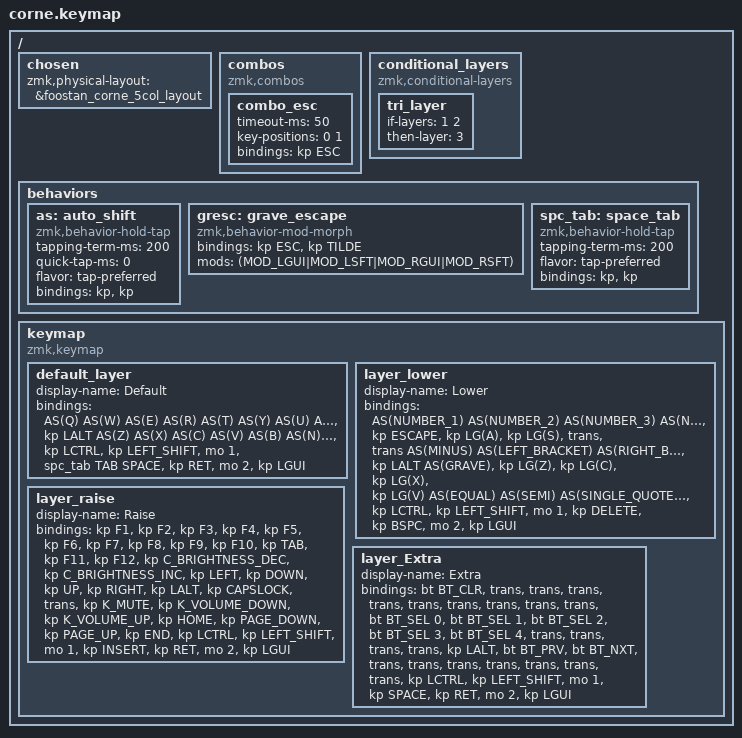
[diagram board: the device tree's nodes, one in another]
/*
 * Copyright (c) 2020 The ZMK Contributors
 *
 * SPDX-License-Identifier: MIT
 */

#include <behaviors.dtsi>
#include <dt-bindings/zmk/keys.h>
#include <dt-bindings/zmk/bt.h>


#define AS(keycode) &as LS(keycode) keycode

/ {
    chosen {
        zmk,physical-layout = &foostan_corne_5col_layout;
    };
 
    combos {
        compatible = "zmk,combos";
        combo_esc {
            timeout-ms = <50>;
            key-positions = <0 1>;
            bindings = <&kp ESC>;
        };
    };

    conditional_layers {
        compatible = "zmk,conditional-layers";
        tri_layer {
            if-layers = <1 2>;
            then-layer = <3>;
        };
    };

    behaviors {
        as: auto_shift {
            compatible = "zmk,behavior-hold-tap";
            #binding-cells = <2>;
            tapping-term-ms = <200>;
            quick-tap-ms = <0>;
            flavor = "tap-preferred";
            bindings = <&kp>, <&kp>;
        };
        
        gresc: grave_escape {
            compatible = "zmk,behavior-mod-morph";
            #binding-cells = <0>;
            bindings = <&kp ESC>, <&kp TILDE>;
            mods = <(MOD_LGUI|MOD_LSFT|MOD_RGUI|MOD_RSFT)>;
        };

        spc_tab: space_tab {
            compatible = "zmk,behavior-hold-tap";
            #binding-cells = <2>;
            tapping-term-ms = <200>;
            flavor = "tap-preferred";
            bindings = <&kp>, <&kp>;
        };
    };
    keymap {
        compatible = "zmk,keymap";

        default_layer {
            display-name = "Default";
            bindings = <
  AS(Q)   AS(W)   AS(E)   AS(R)   AS(T)   AS(Y)   AS(U)   AS(I)   AS(O)   AS(P)   AS(A)   AS(S)   AS(D)   AS(F)   AS(G)   AS(H)   AS(J)   AS(K)   AS(L)  &kp LALT   AS(Z)   AS(X)   AS(C)   AS(V)   AS(B)   AS(N)   AS(M)  AS(COMMA)  AS(DOT)  &kp LCTRL  &kp LEFT_SHIFT   &mo 1  &spc_tab TAB SPACE  &kp RET   &mo 2  &kp LGUI
            >;
        };

        layer_lower {
            display-name = "Lower";
            bindings = <
 AS(NUMBER_1)  AS(NUMBER_2)  AS(NUMBER_3)  AS(NUMBER_4)  AS(NUMBER_5)  AS(NUMBER_6)  AS(NUMBER_7)  AS(NUMBER_8)  AS(NUMBER_9)  AS(NUMBER_0)  &kp ESCAPE  &kp LG(A)  &kp LG(S)  &trans  &trans  AS(MINUS)  AS(LEFT_BRACKET)  AS(RIGHT_BRACKET)  AS(BACKSLASH)  &kp LALT  AS(GRAVE)  &kp LG(Z)  &kp LG(C)  &kp LG(X)  &kp LG(V)  AS(EQUAL)  AS(SEMI)  AS(SINGLE_QUOTE)  AS(SLASH)  &kp LCTRL  &kp LEFT_SHIFT   &mo 1  &kp DELETE  &kp BSPC   &mo 2  &kp LGUI
            >;
        };

        layer_raise {
            display-name = "Raise";
            bindings = <
 &kp F1  &kp F2  &kp F3  &kp F4  &kp F5  &kp F6  &kp F7  &kp F8  &kp F9  &kp F10  &kp TAB  &kp F11  &kp F12  &kp C_BRIGHTNESS_DEC  &kp C_BRIGHTNESS_INC  &kp LEFT  &kp DOWN  &kp UP  &kp RIGHT  &kp LALT  &kp CAPSLOCK     &trans  &kp K_MUTE  &kp K_VOLUME_DOWN  &kp K_VOLUME_UP  &kp HOME  &kp PAGE_DOWN  &kp PAGE_UP  &kp END  &kp LCTRL  &kp LEFT_SHIFT   &mo 1  &kp INSERT  &kp RET   &mo 2  &kp LGUI
            >;
        };

        layer_Extra {
            display-name = "Extra";
            bindings = <
 &bt BT_CLR  &trans  &trans  &trans  &trans  &trans  &trans  &trans  &trans  &trans  &bt BT_SEL 0  &bt BT_SEL 1  &bt BT_SEL 2  &bt BT_SEL 3  &bt BT_SEL 4  &trans  &trans  &trans  &trans  &kp LALT  &bt BT_PRV  &bt BT_NXT  &trans  &trans  &trans  &trans  &trans  &trans  &trans  &kp LCTRL  &kp LEFT_SHIFT   &mo 1  &kp SPACE  &kp RET   &mo 2  &kp LGUI
            >;
        };

    };
};
